# STM32F0xx register map
File version: 1.0
Registers are 32-bit, read-write, reset 0x0 unless marked. A register's access mark holds for its fields unless they carry their own. Offsets are from the block's base; [hi:lo] are bit positions; 'fields as' and 'values as' point back to an identical list.

## USART1 — Universal synchronous asynchronous receiver transmitter
Base 0x40013800
Same registers: USART2 0x40004400
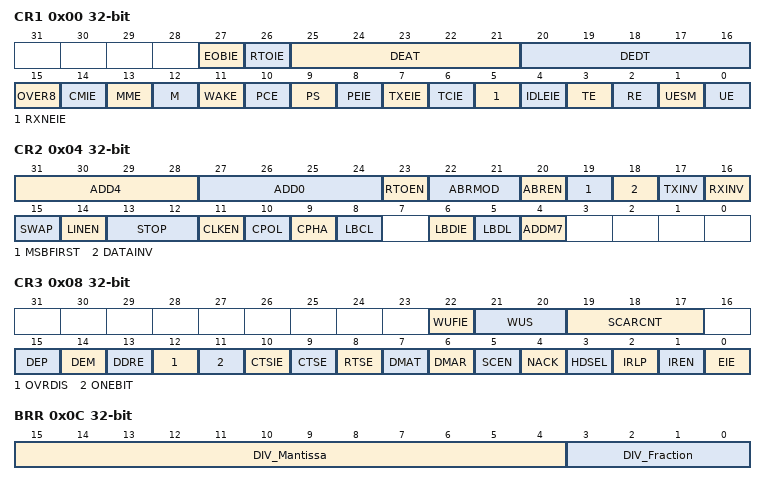
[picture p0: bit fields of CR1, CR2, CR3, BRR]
0x00 CR1 — Control register 1
  [27] EOBIE — End of Block interrupt enable
  [26] RTOIE — Receiver timeout interrupt enable
  [25:21] DEAT — Driver Enable assertion time
  [20:16] DEDT — Driver Enable deassertion time
  [15] OVER8 — Oversampling mode
  [14] CMIE — Character match interrupt enable
  [13] MME — Mute mode enable
  [12] M — Word length
  [11] WAKE — Receiver wakeup method
  [10] PCE — Parity control enable
  [9] PS — Parity selection
  [8] PEIE — PE interrupt enable
  [7] TXEIE — interrupt enable
  [6] TCIE — Transmission complete interrupt enable
  [5] RXNEIE — RXNE interrupt enable
  [4] IDLEIE — IDLE interrupt enable
  [3] TE — Transmitter enable
  [2] RE — Receiver enable
  [1] UESM — USART enable in Stop mode
  [0] UE — USART enable
0x04 CR2 — Control register 2
  [31:28] ADD4 — Address of the USART node
  [27:24] ADD0 — Address of the USART node
  [23] RTOEN — Receiver timeout enable
    0=disabled (Disable the Rising trigger.); 1=enabled (Enable the Rising trigger.)
  [22:21] ABRMOD — Auto baud rate mode
  [20] ABREN — Auto baud rate enable
    values as RTOEN
  [19] MSBFIRST — Most significant bit first
  [18] DATAINV — Binary data inversion
  [17] TXINV — TX pin active level inversion
  [16] RXINV — RX pin active level inversion
  [15] SWAP — Swap TX/RX pins
  [14] LINEN — LIN mode enable
    values as RTOEN
  [13:12] STOP — STOP bits
  [11] CLKEN — Clock enable
    values as RTOEN
  [10] CPOL — Clock polarity
  [9] CPHA — Clock phase
  [8] LBCL — Last bit clock pulse
  [6] LBDIE — LIN break detection interrupt enable
  [5] LBDL — LIN break detection length
  [4] ADDM7 — 7-bit Address Detection/4-bit Address Detection
0x08 CR3 — Control register 3
  [22] WUFIE — Wakeup from Stop mode interrupt enable
  [21:20] WUS — Wakeup from Stop mode interrupt flag selection
  [19:17] SCARCNT — Smartcard auto-retry count
  [15] DEP — Driver enable polarity selection
  [14] DEM — Driver enable mode
  [13] DDRE — DMA Disable on Reception Error
  [12] OVRDIS — Overrun Disable
  [11] ONEBIT — One sample bit method enable
  [10] CTSIE — CTS interrupt enable
  [9] CTSE — CTS enable
  [8] RTSE — RTS enable
  [7] DMAT — DMA enable transmitter
  [6] DMAR — DMA enable receiver
  [5] SCEN — Smartcard mode enable
    values as CR2.RTOEN
  [4] NACK — Smartcard NACK enable
  [3] HDSEL — Half-duplex selection
  [2] IRLP — IrDA low-power
  [1] IREN — IrDA mode enable
    values as CR2.RTOEN
  [0] EIE — Error interrupt enable
0x0C BRR — Baud rate register
  [15:4] DIV_Mantissa — mantissa of USARTDIV
  [3:0] DIV_Fraction — fraction of USARTDIV
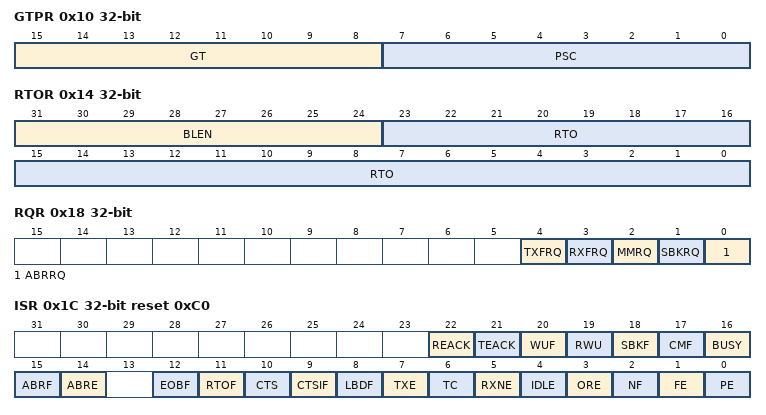
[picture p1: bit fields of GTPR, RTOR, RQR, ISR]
0x10 GTPR — Guard time and prescaler register
  [15:8] GT — Guard time value
  [7:0] PSC — Prescaler value
0x14 RTOR — Receiver timeout register
  [31:24] BLEN — Block Length
  [23:0] RTO — Receiver timeout value
0x18 RQR — Request register
  [4] TXFRQ — Transmit data flush request
  [3] RXFRQ — Receive data flush request
  [2] MMRQ — Mute mode request
  [1] SBKRQ — Send break request
  [0] ABRRQ — Auto baud rate request
0x1C ISR ro reset 0xC0 — Interrupt & status register
  [22] REACK — Receive enable acknowledge flag
  [21] TEACK — Transmit enable acknowledge flag
  [20] WUF — Wakeup from Stop mode flag
  [19] RWU — Receiver wakeup from Mute mode
  [18] SBKF — Send break flag
  [17] CMF — character match flag
  [16] BUSY — Busy flag
  [15] ABRF — Auto baud rate flag
  [14] ABRE — Auto baud rate error
  [12] EOBF — End of block flag
  [11] RTOF — Receiver timeout
  [10] CTS — CTS flag
  [9] CTSIF — CTS interrupt flag
  [8] LBDF — LIN break detection flag
  [7] TXE — Transmit data register empty
  [6] TC — Transmission complete
  [5] RXNE — Read data register not empty
  [4] IDLE — Idle line detected
  [3] ORE — Overrun error
  [2] NF — Noise detected flag
  [1] FE — Framing error
  [0] PE — Parity error
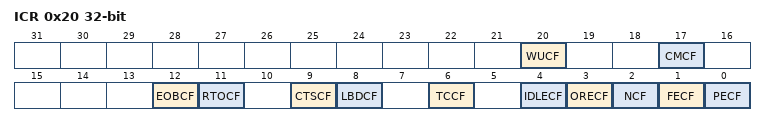
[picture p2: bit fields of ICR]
0x20 ICR — Interrupt flag clear register
  [20] WUCF — Wakeup from Stop mode clear flag
  [17] CMCF — Character match clear flag
  [12] EOBCF — End of timeout clear flag
  [11] RTOCF — Receiver timeout clear flag
  [9] CTSCF — CTS clear flag
  [8] LBDCF — LIN break detection clear flag
  [6] TCCF — Transmission complete clear flag
  [4] IDLECF — Idle line detected clear flag
  [3] ORECF — Overrun error clear flag
  [2] NCF — Noise detected clear flag
  [1] FECF — Framing error clear flag
  [0] PECF — Parity error clear flag
0x24 RDR ro — Receive data register
  [8:0] RDR — Receive data value
0x28 TDR — Transmit data register
  [8:0] TDR — Transmit data value
